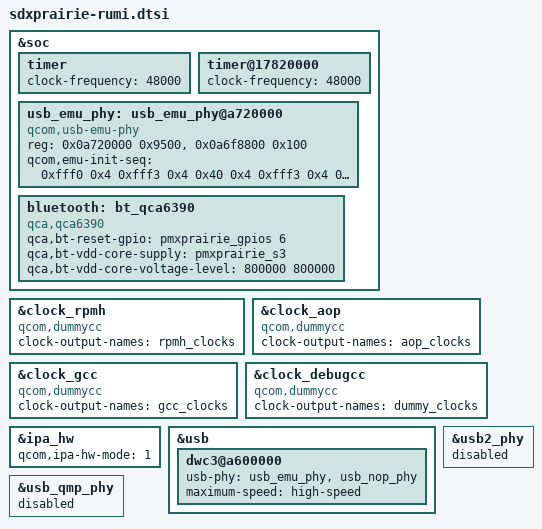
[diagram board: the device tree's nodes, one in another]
/* Copyright (c) 2018-2019, The Linux Foundation. All rights reserved.
 *
 * This program is free software; you can redistribute it and/or modify
 * it under the terms of the GNU General Public License version 2 and
 * only version 2 as published by the Free Software Foundation.
 *
 * This program is distributed in the hope that it will be useful,
 * but WITHOUT ANY WARRANTY; without even the implied warranty of
 * MERCHANTABILITY or FITNESS FOR A PARTICULAR PURPOSE.  See the
 * GNU General Public License for more details.
 */

#include "sdxprairie-pmic-overlay.dtsi"

&soc {
	timer {
		clock-frequency = <48000>;
	};

	timer@17820000 {
		clock-frequency = <48000>;
	};

	usb_emu_phy: usb_emu_phy@a720000 {
		compatible = "qcom,usb-emu-phy";
		reg = <0x0a720000 0x9500>,
		      <0x0a6f8800 0x100>;
		reg-names = "base", "qcratch_base";

		qcom,emu-init-seq = <0xfff0 0x4
				     0xfff3 0x4
				     0x40 0x4
				     0xfff3 0x4
				     0xfff0 0x4
				     0x100000 0x20
				     0x0 0x20
				     0x1a0 0x20
				     0x100000 0x3c
				     0x0 0x3c
				     0x10060 0x3c
				     0x0 0x4>;
	};
};

&clock_rpmh {
	compatible = "qcom,dummycc";
	clock-output-names = "rpmh_clocks";
};

&clock_aop {
	compatible = "qcom,dummycc";
	clock-output-names = "aop_clocks";
};

&clock_gcc {
	compatible = "qcom,dummycc";
	clock-output-names = "gcc_clocks";
};

&clock_debugcc {
	compatible = "qcom,dummycc";
	clock-output-names = "dummy_clocks";
};

&ipa_hw {
	qcom,ipa-hw-mode = <1>; /* IPA hw type = Virtual */
};

&usb {
	/delete-property/ iommus;
	/delete-property/ extcon;
	dwc3@a600000 {
		usb-phy = <&usb_emu_phy>, <&usb_nop_phy>;
		maximum-speed = "high-speed";
	};
};

&usb_qmp_phy {
	status = "disabled";
};

&usb2_phy {
	status = "disabled";
};

&soc {
	bluetooth: bt_qca6390 {
		compatible = "qca,qca6390";
		qca,bt-reset-gpio = <&pmxprairie_gpios 6 0>;
		qca,bt-vdd-core-supply = <&pmxprairie_s3>; /* VDD_PMU_AON_I */
		qca,bt-vdd-core-voltage-level = <800000 800000>;
	};
};
